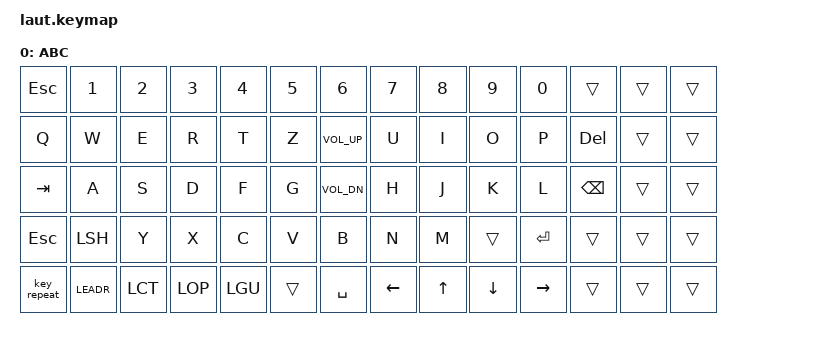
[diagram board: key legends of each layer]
#include <behaviors.dtsi>
#include <dt-bindings/zmk/keys.h>

#define xxxx &none
#define ____ &trans
#define LCT ks(LCTRL)
#define LGU ks(LGUI)
#define LOP ks(LALT)
#define LSH ks(LSHFT)
#define RCT ks(RCTRL)
#define RGU ks(RGUI)
#define ROP ks(RALT)
#define RSH ks(RSHFT)
#define REP &key_repeat
#define VOLDN &kp C_VOL_DN
#define VOLUP &kp C_VOL_UP

/ { 

    keymap {
        compatible = "zmk,keymap";
        abc {
            display-name = "ABC";
            bindings = <
            //  1       2       3       4       5       6       7           8           9           10          11          12          13      14
                &kp ESC &kp N1  &kp N2  &kp N3  &kp N4  &kp N5  &kp N6      &kp N7      &kp N8      &kp N9      &kp N0      ____        ____    ____   
                &kp Q   &kp W   &kp E   &kp R   &kp T   &kp Z   VOLUP       &kp U       &kp I       &kp O       &kp P       &kp DEL     ____    ____ 
                &kp TAB &kp A   &kp S   &kp D   &kp F   &kp G   VOLDN       &kp H       &kp J       &kp K       &kp L       &kp BSPC    ____    ____ 
                &kp ESC LSH     &kp Y   &kp X   &kp C   &kp V   &kp B       &kp N       &kp M       ____        &kp ENTER   ____        ____    ____ 
                REP     LEADR   LCT     LOP     LGU     ____    &kp SPACE   &kp LEFT    &kp UP      &kp DOWN    &kp RIGHT   ____        ____    ____ 
            >; 
        };
    }; 
};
